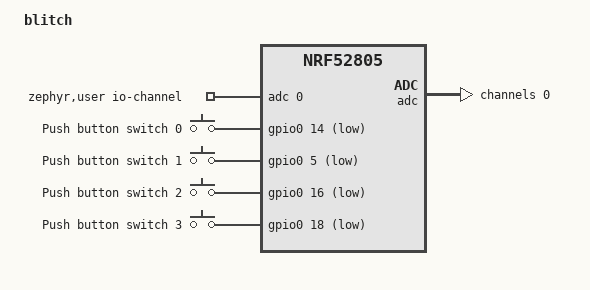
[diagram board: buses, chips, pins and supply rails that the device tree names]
// Copyright (c) 2024 Nordic Semiconductor ASA
// SPDX-License-Identifier: Apache-2.0

/dts-v1/;
#include <nordic/nrf52805_caaa.dtsi>

/ {
	model = "blitch";
	compatible = "dadantech,blitch";

	zephyr,user {
		io-channels = <&adc 0>;
	};
	
	chosen {
		zephyr,sram = &sram0;
		zephyr,flash = &flash0;
		zephyr,code-partition = &slot0_partition;
	};

	// leds {
	// 	compatible = "gpio-leds";
	// 	led0: led_0 {
	// 		gpios = <&gpio0 12 GPIO_ACTIVE_LOW>;
	// 		label = "Green LED 0";
	// 	};
	// };

	buttons {
		compatible = "gpio-keys";
		button0: button_0 {
			gpios = <&gpio0 14 (GPIO_PULL_UP | GPIO_ACTIVE_LOW)>;
			label = "Push button switch 0";
			zephyr,code = <INPUT_KEY_0>;
		};
		button1: button_1 {
			gpios = <&gpio0 5 (GPIO_PULL_UP | GPIO_ACTIVE_LOW)>;
			label = "Push button switch 1";
			zephyr,code = <INPUT_KEY_1>;
		};
		button2: button_2 {
			gpios = <&gpio0 16 (GPIO_PULL_UP | GPIO_ACTIVE_LOW)>;
			label = "Push button switch 2";
			zephyr,code = <INPUT_KEY_2>;
		};
		button3: button_3 {
			gpios = <&gpio0 18 (GPIO_PULL_UP | GPIO_ACTIVE_LOW)>;
			label = "Push button switch 3";
			zephyr,code = <INPUT_KEY_3>;
		};
	};
};

&gpio0 {
	status = "okay";
	sense-edge-mask = < 0xffffffff >;
};

&gpiote {
	status = "okay";
};

&flash0 {
	partitions {
		compatible = "fixed-partitions";
		#address-cells = <1>;
		#size-cells = <1>;

		boot_partition: partition@0 {
			label = "mcuboot";
			reg = <0x0 0xc000>;
		};
		slot0_partition: partition@c000 {
			label = "image-0";
			reg = <0xc000 0xa000>;
		};
		slot1_partition: partition@16000 {
			label = "image-1";
			reg = <0x16000 0xa000>;
		};
		scratch_partition: partition@20000 {
			label = "image-scratch";
			reg = <0x20000 0xa000>;
		};
		storage_partition: partition@2a000 {
			label = "storage";
			reg = <0x2a000 0x6000>;
		};
	};
};

&adc {
	#address-cells = <1>;
	#size-cells = <0>;
	status = "okay";
	channel@0 {
		reg = <0>;
		zephyr,gain = "ADC_GAIN_1_6";
		zephyr,reference = "ADC_REF_INTERNAL";
		zephyr,acquisition-time = <ADC_ACQ_TIME_DEFAULT>;
		zephyr,input-positive = <NRF_SAADC_VDD >;
		zephyr,resolution = <12>;
	};
};


